# a34g43x register map
Vendor: ABOV Semiconductor Co., Ltd.; File version: 1.0
CPU: CM4 r0p1, little endian, MPU, FPU, VTOR, 4 interrupt priority bits
Registers are 32-bit, read-write, reset 0x0 unless marked. A register's access mark holds for its fields unless they carry their own. Offsets are from the block's base; [hi:lo] are bit positions; {n}, {i} and the like mark numbered series; 'fields as' and 'values as' point back to an identical list.

## AES128 — Advanced Encryption Standard 128
Base 0x40000500
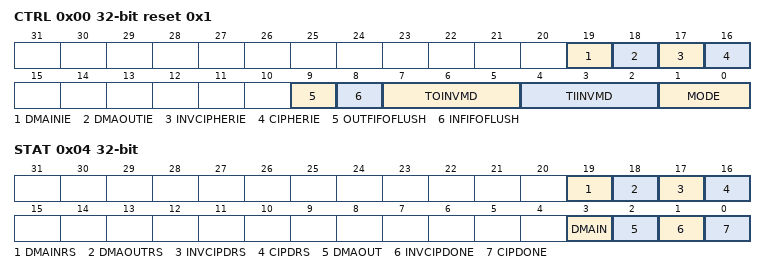
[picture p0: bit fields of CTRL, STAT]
0x00 CTRL reset 0x1 — AES Control Register
  [19] DMAINIE — AES DMA Input Complete Interrupt Enable
    0=Disable; 1=Enable
  [18] DMAOUTIE — AES DMA Output Complete Interrupt Enable
    0=Disable; 1=Enable
  [17] INVCIPHERIE — AES Inverse Cipher Mode Complete Interrupt Enable
    0=Disable; 1=Enable
  [16] CIPHERIE — AES Cipher Mode Complete Interrupt Enable
    0=Disable; 1=Enable
  [9] OUTFIFOFLUSH — AES Output FIFO Erase Bit(Auto Clear)
    0=Disable; 1=Enable
  [8] INFIFOFLUSH — AES Input FIFO Erase Bit(Auto Clear)
    0=Disable; 1=Enable
  [7:5] TOINVMD — AES TEXT OUT Arrange Mode Setting Bit
    0=Default WORD Row(LSB); 1=WORD_INV (WORD Inverse Mode(MSB)); 2=BYTE_INV_INWORD (BYTE Inverse in WORD Mode(MSB)); 4=BYTE_INV (BYTE Inverse Mode(MSB))
  [4:2] TIINVMD — AES TEXT IN Arrange Mode Setting Bit
    values as TOINVMD
  [1:0] MODE — AES Mode Selection Bit
    1=Cipher Mode; 2=Inverse Cipher Mode
0x04 STAT — AES Status Register
  [19] DMAINRS ro — AES DMA Input Complete Status Bit(Raw data)
  [18] DMAOUTRS ro — AES DMA Output Complete Status Bit(Raw data)
  [17] INVCIPDRS ro — AES DMA Input Complete Status Bit(Raw data)
  [16] CIPDRS ro — AES DMA Input Complete Status Bit(Raw data)
  [3] DMAIN — AES DMA Input Complete Flag Bit
    0=Not_Complete; 1=Done_Clear (Inverse Ciper Done (to clear write '1'))
  [2] DMAOUT — AES DMA Output Complete Flag Bit
    values as DMAIN
  [1] INVCIPDONE — AES Inverse Cipher Done Flag Bit
    values as DMAIN
  [0] CIPDONE — AES Cipher Done Flag Bit
    0=Not_Complete; 1=Done_Clear (Ciper Done (to clear write '1'))
0x08 INFIFO wo — AES Input FIFO Register
  [31:0] TEXTIN — TEST IN FIFO Register
0x0C OUTFIFO ro — AES Output FIFO Register
  [31:0] TEXTOUT — TEST OUT FIFO Register
{0x10+4i} KEYIN{i} (i=0..3) — AES KEY IN Register {i}
  [31:0] KEYIND{i} — KEY IN Value Register {i}
{0x20+4i} TEXTIN{i} ro (i=0..3) — AES TEXT IN {i} Register
  [31:0] TEXTIN{i} — TEST IN Value Register
{0x30+4i} TEXTOUT{i} ro (i=0..3) — AES TEXT OUT Register {i}
  [31:0] OUTD{i} — TEXT OUT Value Bit

## RNG — Random Number Generator
Base 0x40000A00
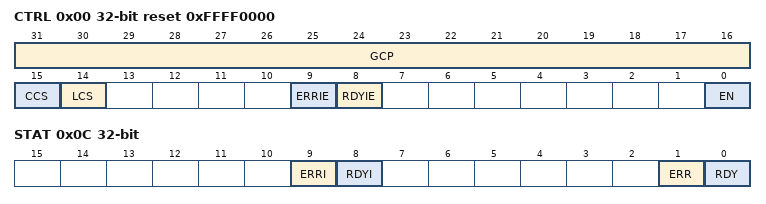
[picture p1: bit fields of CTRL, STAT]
0x00 CTRL reset 0xFFFF0000 — RNG Control Register
  [31:16] GCP — Generation Counter Parameter
  [15] CCS — CASR Clock Selection Bit
    0=RNG_OSC2; 1=HSI
  [14] LCS — LFSR Clock Selection Bit
    0=RNG_OSC1; 1=LSI (HSI)
  [9] ERRIE — Error Interrupt Enable Bit
    0=Disable interrupt; 1=Enable interrupt
  [8] RDYIE — RNGD Data Ready Interrupt Enable Bit
    0=Disable interrupt; 1=Enable interrupt
  [0] EN — RNG Start Bit
    0=STOP (RNG STOP); 1=START (RNG START)
0x04 SEED — RNG SEED Register
  [31:0] SEED — RND Seed Setting Bit
0x08 RNGD ro — RNG Random number data register
  [31:0] RNGD — Random number generation data bit
0x0C STAT — RNG Status Register
  [9] ERRI ro — Error Interrupt Flag Bit
  [8] RDYI ro — RNGD Data Ready Interrupt Flag Bit
  [1] ERR — Error Status Bit, Writing a '1' to the bit clears ERR bit or ERRI bit
  [0] RDY — RNGD Ready Status Bit, Writing a '1' to the bit clears RDYI bit

## CRC — CYCLIC REDUNDANCY CHECK AND CHECKSUM
Base 0x41002000
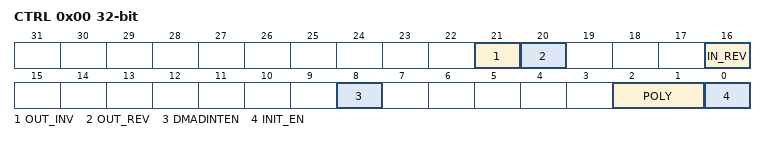
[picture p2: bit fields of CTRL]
0x00 CTRL — CRC Control Register
  [21] OUT_INV — CRC Output Data Inversion Enable bit
  [20] OUT_REV — CRC Output Data Reverse Enable Bit
  [16] IN_REV — Input Data Reverse Mode Selection Bit
  [8] DMADINTEN — DMA Done Interrupt Enable Bit
  [2:1] POLY — Polynomal Selection Bit
    0=CRC32 (0x04C1_1DB7); 1=CRC16_USB (0x8005); 2=CRC16_CCITT (0x1021); 3=CRC8_CCITT (0x07)
  [0] INIT_EN wo — CRC Init Register Apply Bit
0x04 INIT reset 0xFFFFFFFF — CRC Init value Register
  [31:0] INIT — CRC Initial Value
0x08 IDR wo — CRC Input Data Register
  [31:0] IDR — CRC Input Data Bit
0x08 ODR ro reset 0xFFFFFFFF — CRC Output Data Register
  [31:0] ODR — CRC Output Data Bit
0x0C STAT — CRC Status Register
  [8] DMADINT — DMA Done Interrupt Flag Bit
